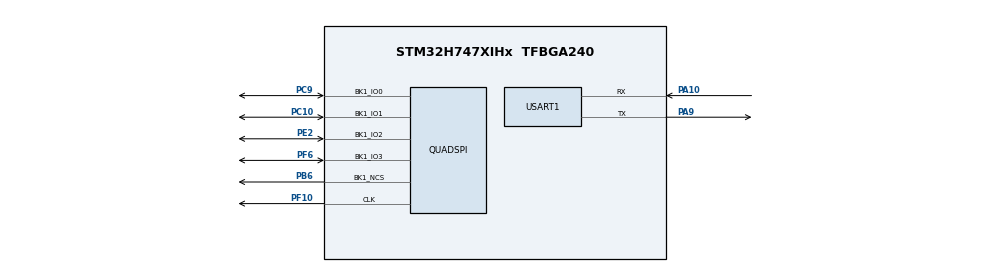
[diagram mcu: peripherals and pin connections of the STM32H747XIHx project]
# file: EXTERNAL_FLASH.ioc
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CortexM4.IPs=BDMA,DMA,FATFS_M4\:I,FREERTOS_M4\:I,IWDG2\:I,MDMA,NVIC2\:I,RCC,USB_DEVICE_M4\:I,USB_HOST_M4\:I,WWDG2\:I,ADC1\:I,DCMI\:I,TIM3\:I,DEBUG,PDM2PCM_M4\:I,PWR,RESMGR_UTILITY,SYS_M4\:I,CORTEX_M4\:I,OPENAMP_M4\:I,VREFBUF,GPIO
CortexM7.IPs=BDMA\:I,DMA\:I,FATFS_M7\:I,FREERTOS_M7\:I,IWDG1\:I,MDMA\:I,NVIC1\:I,RCC\:I,USB_DEVICE_M7\:I,USB_HOST_M7\:I,WWDG1\:I,CORTEX_M7\:I,DEBUG\:I,PDM2PCM_M7\:I,PWR\:I,RESMGR_UTILITY\:I,SYS\:I,OPENAMP_M7\:I,VREFBUF\:I,GPIO\:I,USART1\:I,QUADSPI\:I
Mcu.Family=STM32H7
Mcu.Name=STM32H747XIHx
Mcu.Package=TFBGA240
NVIC1.PriorityGroup=NVIC_PRIORITYGROUP_4
NVIC2.PriorityGroup=NVIC_PRIORITYGROUP_4
PA10.Mode=Asynchronous
PA10.PinAttribute=CortexM7
PA10.Signal=USART1_RX
PA9.Mode=Asynchronous
PA9.PinAttribute=CortexM7
PA9.Signal=USART1_TX
PB6.Mode=Single Bank 1
PB6.PinAttribute=CortexM7
PB6.Signal=QUADSPI_BK1_NCS
PC10.Mode=Single Bank 1
PC10.PinAttribute=CortexM7
PC10.Signal=QUADSPI_BK1_IO1
PC9.Mode=Single Bank 1
PC9.PinAttribute=CortexM7
PC9.Signal=QUADSPI_BK1_IO0
PE2.Mode=Single Bank 1
PE2.PinAttribute=CortexM7
PE2.Signal=QUADSPI_BK1_IO2
PF10.Mode=Single Bank 1
PF10.PinAttribute=CortexM7
PF10.Signal=QUADSPI_CLK
PF6.Mode=Single Bank 1
PF6.PinAttribute=CortexM7
PF6.Signal=QUADSPI_BK1_IO3
ProjectManager.HeapSize=M4-0x200,M7-0x200
ProjectManager.StackSize=M4-0x400,M7-0x400
ProjectManager.TargetToolchain=STM32CubeIDE
QUADSPI.ClockMode=QSPI_CLOCK_MODE_3
QUADSPI.ClockPrescaler=1
RCC.ADCFreq_Value=75000000
RCC.APB1Freq_Value=100000000
RCC.APB2Freq_Value=100000000
RCC.APB3Freq_Value=100000000
RCC.APB4Freq_Value=100000000
RCC.CortexFreq_Value=400000000
RCC.D1PPRE=RCC_APB3_DIV2
RCC.D2PPRE1=RCC_APB1_DIV2
RCC.D2PPRE2=RCC_APB2_DIV2
RCC.D3PPRE=RCC_APB4_DIV2
RCC.DIVM1=4
RCC.DIVM2=4
RCC.DIVN1=50
RCC.DIVN2=9
RCC.HCLKFreq_Value=200000000
RCC.HPRE=RCC_HCLK_DIV2
RCC.PLL2FRACN=3072
RCC.PLL3FRACN=0
RCC.PLLFRACN=0
RCC.PWR_Regulator_Voltage_Scale=PWR_REGULATOR_VOLTAGE_SCALE1
RCC.SYSCLKFreq_VALUE=400000000
RCC.SYSCLKSource=RCC_SYSCLKSOURCE_PLLCLK
RCC.SupplySource=PWR_DIRECT_SMPS_SUPPLY
RCC.USBFreq_Value=400000000
USART1.VirtualMode-Asynchronous=VM_ASYNC
VP_SYS_M4_VS_Systick.Mode=SysTick
board=STM32H747I-DISCO

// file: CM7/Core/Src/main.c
/* USER CODE BEGIN Header */
/**
  ******************************************************************************
  * @file           : main.c
  * @brief          : Main program body
  ******************************************************************************
  * @attention
  *
  * Copyright (c) 2024 STMicroelectronics.
  * All rights reserved.
  *
  * This software is licensed under terms that can be found in the LICENSE file
  * in the root directory of this software component.
  * If no LICENSE file comes with this software, it is provided AS-IS.
  *
  ******************************************************************************
  */
/* USER CODE END Header */
#include "main.h"
#include "usart.h"
#include "gpio.h"

/* USER CODE BEGIN Includes */
#include "stm32h747i_discovery_qspi.h"
/* USER CODE END Includes */

/* USER CODE BEGIN PD */

#ifndef HSEM_ID_0
#define HSEM_ID_0 (0U) /* HW semaphore 0*/
#endif

/* USER CODE END PD */

void SystemClock_Config(void);

int main(void)
{
/* USER CODE BEGIN Boot_Mode_Sequence_0 */
  int32_t timeout;
/* USER CODE END Boot_Mode_Sequence_0 */

/* USER CODE BEGIN Boot_Mode_Sequence_1 */
  /* Wait until CPU2 boots and enters in stop mode or timeout*/
  timeout = 0xFFFF;
  while((__HAL_RCC_GET_FLAG(RCC_FLAG_D2CKRDY) != RESET) && (timeout-- > 0));
  if ( timeout < 0 )
  {
  Error_Handler();
  }
/* USER CODE END Boot_Mode_Sequence_1 */
  /* MCU Configuration--------------------------------------------------------*/

  /* Reset of all peripherals, Initializes the Flash interface and the Systick. */
  HAL_Init();

  /* Configure the system clock */
  SystemClock_Config();
/* USER CODE BEGIN Boot_Mode_Sequence_2 */
/* When system initialization is finished, Cortex-M7 will release Cortex-M4 by means of
HSEM notification */
/*HW semaphore Clock enable*/
__HAL_RCC_HSEM_CLK_ENABLE();
/*Take HSEM */
HAL_HSEM_FastTake(HSEM_ID_0);
/*Release HSEM in order to notify the CPU2(CM4)*/
HAL_HSEM_Release(HSEM_ID_0,0);
/* wait until CPU2 wakes up from stop mode */
timeout = 0xFFFF;
while((__HAL_RCC_GET_FLAG(RCC_FLAG_D2CKRDY) == RESET) && (timeout-- > 0));
if ( timeout < 0 )
{
Error_Handler();
}
/* USER CODE END Boot_Mode_Sequence_2 */

  /* Initialize all configured peripherals */
  MX_GPIO_Init();
  MX_USART1_UART_Init();

  /* Infinite loop */
  /* USER CODE BEGIN WHILE */
  // QSPI basic configuration and hardware initialization.
  BSP_QSPI_Init_t init;
  init.InterfaceMode	= MT25TL01G_QPI_MODE;
  init.TransferRate		= MT25TL01G_DTR_TRANSFER ;
  init.DualFlashMode	= MT25TL01G_DUALFLASH_ENABLE;
  if (BSP_QSPI_Init(0, &init) != BSP_ERROR_NONE) {	// Initialization and check error.
	  Error_Handler();
  }

  // Make the user to access to the External Flash with address mode.
  // (i.e., You don't need to call BSP_QSPI_Write or Read function. Just allocate the 0x90000000 address to a variable like the next line.
  if (BSP_QSPI_EnableMemoryMappedMode(0) != BSP_ERROR_NONE) {	// Make the QSPI MemoryMappedMode and check error.
	  Error_Handler();
  }

  uint8_t *flash_memory = (uint8_t *)(0x90000000);	//

  uint8_t flash_data = flash_memory[0];
  while (1)
  {
    /* USER CODE END WHILE */

  }
}

void SystemClock_Config(void)
{
  RCC_OscInitTypeDef RCC_OscInitStruct = {0};
  RCC_ClkInitTypeDef RCC_ClkInitStruct = {0};

  /** Supply configuration update enable
  */
  HAL_PWREx_ConfigSupply(PWR_DIRECT_SMPS_SUPPLY);

  /** Configure the main internal regulator output voltage
  */
  __HAL_PWR_VOLTAGESCALING_CONFIG(PWR_REGULATOR_VOLTAGE_SCALE1);

  while(!__HAL_PWR_GET_FLAG(PWR_FLAG_VOSRDY)) {}

  /** Initializes the RCC Oscillators according to the specified parameters
  * in the RCC_OscInitTypeDef structure.
  */
  RCC_OscInitStruct.OscillatorType = RCC_OSCILLATORTYPE_HSI;
  RCC_OscInitStruct.HSIState = RCC_HSI_DIV1;
  RCC_OscInitStruct.HSICalibrationValue = RCC_HSICALIBRATION_DEFAULT;
  RCC_OscInitStruct.PLL.PLLState = RCC_PLL_ON;
  RCC_OscInitStruct.PLL.PLLSource = RCC_PLLSOURCE_HSI;
  RCC_OscInitStruct.PLL.PLLM = 4;
  RCC_OscInitStruct.PLL.PLLN = 50;
  RCC_OscInitStruct.PLL.PLLP = 2;
  RCC_OscInitStruct.PLL.PLLQ = 2;
  RCC_OscInitStruct.PLL.PLLR = 2;
  RCC_OscInitStruct.PLL.PLLRGE = RCC_PLL1VCIRANGE_3;
  RCC_OscInitStruct.PLL.PLLVCOSEL = RCC_PLL1VCOWIDE;
  RCC_OscInitStruct.PLL.PLLFRACN = 0;
  if (HAL_RCC_OscConfig(&RCC_OscInitStruct) != HAL_OK)
  {
    Error_Handler();
  }

  /** Initializes the CPU, AHB and APB buses clocks
  */
  RCC_ClkInitStruct.ClockType = RCC_CLOCKTYPE_HCLK|RCC_CLOCKTYPE_SYSCLK
                              |RCC_CLOCKTYPE_PCLK1|RCC_CLOCKTYPE_PCLK2
                              |RCC_CLOCKTYPE_D3PCLK1|RCC_CLOCKTYPE_D1PCLK1;
  RCC_ClkInitStruct.SYSCLKSource = RCC_SYSCLKSOURCE_PLLCLK;
  RCC_ClkInitStruct.SYSCLKDivider = RCC_SYSCLK_DIV1;
  RCC_ClkInitStruct.AHBCLKDivider = RCC_HCLK_DIV2;
  RCC_ClkInitStruct.APB3CLKDivider = RCC_APB3_DIV2;
  RCC_ClkInitStruct.APB1CLKDivider = RCC_APB1_DIV2;
  RCC_ClkInitStruct.APB2CLKDivider = RCC_APB2_DIV2;
  RCC_ClkInitStruct.APB4CLKDivider = RCC_APB4_DIV2;

  if (HAL_RCC_ClockConfig(&RCC_ClkInitStruct, FLASH_LATENCY_2) != HAL_OK)
  {
    Error_Handler();
  }
}

void Error_Handler(void)
{
  __disable_irq();
  while (1)
  {
  }
}
